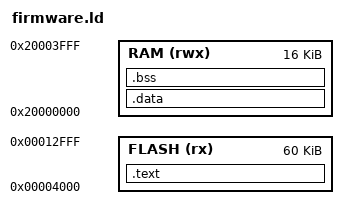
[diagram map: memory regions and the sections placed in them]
ENTRY(firmware_main)

MEMORY
{
  FLASH (rx)  : ORIGIN = 0x00004000, LENGTH = 60K
  RAM   (rwx) : ORIGIN = 0x20000000, LENGTH = 16K
}

SECTIONS
{
  .text : {
    *(.text*)
    *(.rodata*)
  } > FLASH

  .data : {
    *(.data*)
  } > RAM

  .bss : {
    *(.bss*)
    *(COMMON)
  } > RAM
}
